# dm64lc_cslr_vpss_001 register map
Vendor: Texas Instruments
Peripheral module from a debugger description file.
Registers are 32-bit, access not given, reset 0x0 unless marked. A register's access mark holds for its fields unless they carry their own. Offsets are as the file gives them; lines under a group give offsets from that group; [hi:lo] are bit positions; {n}, {i} and the like mark numbered series; 'fields as' and 'values as' point back to an identical list; <NAME> marks a mode.

## VPSS — Video Processing Subsystem - read-only status registers (spec version: 1.00.w.23)
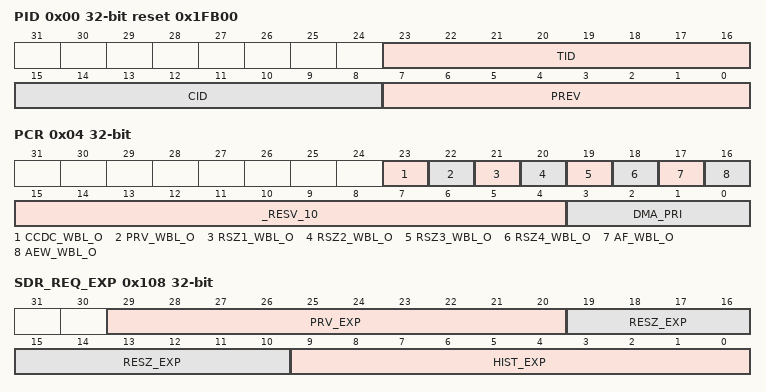
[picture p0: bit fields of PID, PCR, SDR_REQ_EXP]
0x00 PID reset 0x1FB00 — Peripheral Revision and Class Information
  [23:16] TID ro — Peripheral Identificiation VPSS
  [15:8] CID ro — Class Identification VPSS
  [7:0] PREV ro — Peripheral Revision Number Initial Revision
0x04 PCR — VPSS Control Register
  [23] CCDC_WBL_O rw — Write buffer memory overflow (CCDC): 0:(NOOVERFLOW), 1:(OVERFLOW)
  [22] PRV_WBL_O rw — Write buffer memory overflow (Preview engine) 0:(NOOVERFLOW), 1:(OVERFLOW)
  [22-n] RSZ{n}_WBL_O rw (n=1..4) — Write buffer memory overflow (Resizer line {n}) 0:(NOOVERFLOW), 1:(OVERFLOW)
  [17] AF_WBL_O rw — Write buffer memory overflow (AF) 0:(NOOVERFLOW), 1:(OVERFLOW)
  [16] AEW_WBL_O rw — Write buffer memory overflow (AE/WB) 0:(NOOVERFLOW), 1:(OVERFLOW)
  [15:4] _RESV_10 — (access N)
  [3:0] DMA_PRI rw — VBUSM priority in the system (to the DDR EMIF) The default should be the highest priority in the system
0x108 SDR_REQ_EXP — SDRAM non real-time read request expand
  [29:20] PRV_EXP rw — Preview read request expand Delay to allow between consecutive read requests from the Preview module. Units are VPSS clock cycles (153/198 MHz in Normal/Turbo modes). Since VPSS DMA priority is typically set to the highest in the SoC for real_time requirements, this is for spreading any non real_time reads with respect to the other traffic in the system to minimize the potential of locking out other requests for the duration of a frame being read from DDR/SDR.
  [19:10] RESZ_EXP rw — Resizer read request expand Delay to allow between consecutive read requests from the Resizer module. Units are VPSS clock cycles (153/198 MHz in Normal/Turbo modes), multiplied by 32. Since VPSS DMA priority is typically set to the highest in the SoC for real_time requirements, this is for spreading any non real_time reads with respect to the other traffic in the system to minimize the potential of locking out other requests for the duration of a frame being read from DDR/SDR.
  [9:0] HIST_EXP rw — Histogram read request expand Delay to allow between consecutive read requests from the Histogram module. Units are VPSS clock cycles (153/198 MHz in Normal/Turbo modes). Since VPSS DMA priority is typically set to the highest in the SoC for real_time requirements, this is for spreading any non real_time reads with respect to the other traffic in the system to minimize the potential of locking out other requests for the duration of a frame being read from DDR/SDR.
